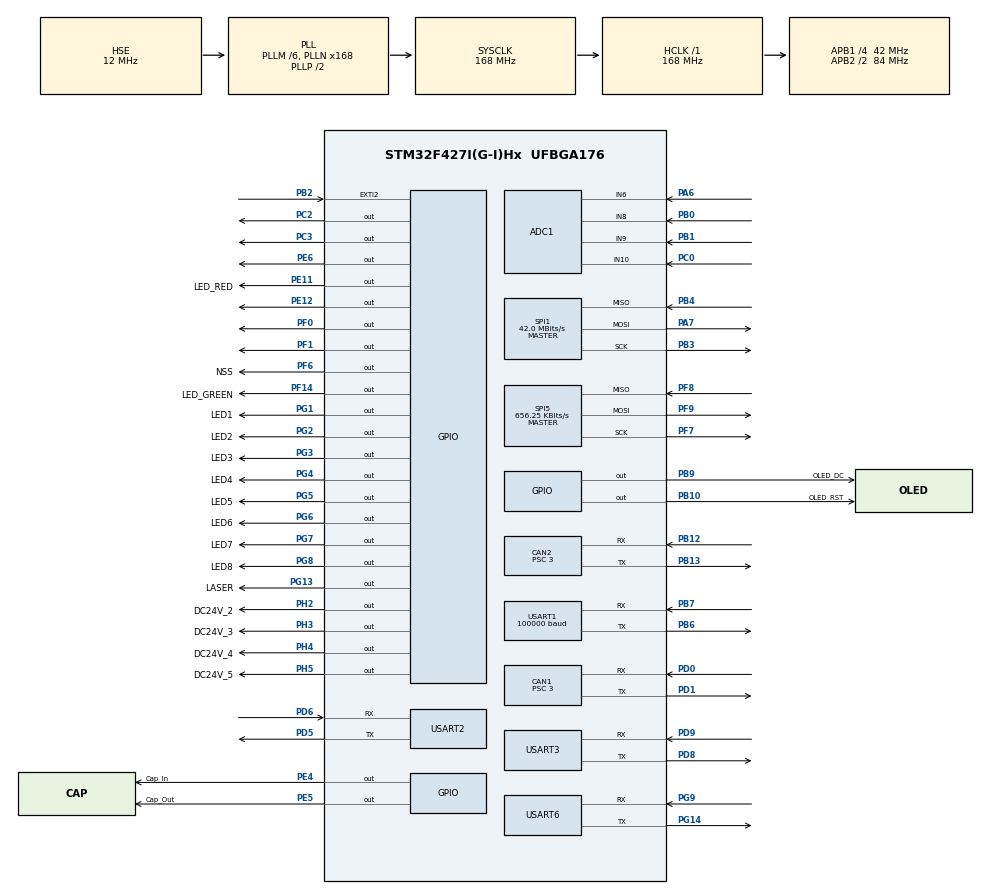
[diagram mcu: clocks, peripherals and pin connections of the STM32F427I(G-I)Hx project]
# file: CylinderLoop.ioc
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ADC1.Channel-0\#ChannelRegularConversion=ADC_CHANNEL_6
ADC1.NbrOfConversionFlag=1
ADC1.Rank-0\#ChannelRegularConversion=1
ADC1.SamplingTime-0\#ChannelRegularConversion=ADC_SAMPLETIME_3CYCLES
ADC1.master=1
CAN1.BS1=CAN_BS1_9TQ
CAN1.BS2=CAN_BS2_4TQ
CAN1.CalculateTimeBit=1000
CAN1.CalculateTimeQuantum=71.42857142857143
CAN1.Prescaler=3
CAN2.BS1=CAN_BS1_9TQ
CAN2.BS2=CAN_BS2_4TQ
CAN2.CalculateTimeBit=1000
CAN2.CalculateTimeQuantum=71.42857142857143
CAN2.Prescaler=3
Dma.Request0=USART3_RX
Dma.Request1=USART6_RX
Dma.Request2=USART6_TX
Dma.Request3=USART1_RX
Dma.Request4=USART3_TX
Dma.Request5=SPI1_TX
Dma.Request6=SPI1_RX
Dma.SPI1_RX.6.Direction=DMA_PERIPH_TO_MEMORY
Dma.SPI1_RX.6.FIFOMode=DMA_FIFOMODE_DISABLE
Dma.SPI1_RX.6.Instance=DMA2_Stream0
Dma.SPI1_RX.6.MemDataAlignment=DMA_MDATAALIGN_BYTE
Dma.SPI1_RX.6.MemInc=DMA_MINC_ENABLE
Dma.SPI1_RX.6.Mode=DMA_NORMAL
Dma.SPI1_RX.6.PeriphDataAlignment=DMA_PDATAALIGN_BYTE
Dma.SPI1_RX.6.PeriphInc=DMA_PINC_DISABLE
Dma.SPI1_RX.6.Priority=DMA_PRIORITY_LOW
Dma.SPI1_TX.5.Direction=DMA_MEMORY_TO_PERIPH
Dma.SPI1_TX.5.FIFOMode=DMA_FIFOMODE_DISABLE
Dma.SPI1_TX.5.Instance=DMA2_Stream5
Dma.SPI1_TX.5.MemDataAlignment=DMA_MDATAALIGN_BYTE
Dma.SPI1_TX.5.MemInc=DMA_MINC_ENABLE
Dma.SPI1_TX.5.Mode=DMA_NORMAL
Dma.SPI1_TX.5.PeriphDataAlignment=DMA_PDATAALIGN_BYTE
Dma.SPI1_TX.5.PeriphInc=DMA_PINC_DISABLE
Dma.SPI1_TX.5.Priority=DMA_PRIORITY_LOW
Dma.USART1_RX.3.Direction=DMA_PERIPH_TO_MEMORY
Dma.USART1_RX.3.FIFOMode=DMA_FIFOMODE_DISABLE
Dma.USART1_RX.3.Instance=DMA2_Stream2
Dma.USART1_RX.3.MemDataAlignment=DMA_MDATAALIGN_BYTE
Dma.USART1_RX.3.MemInc=DMA_MINC_ENABLE
Dma.USART1_RX.3.Mode=DMA_NORMAL
Dma.USART1_RX.3.PeriphDataAlignment=DMA_PDATAALIGN_BYTE
Dma.USART1_RX.3.PeriphInc=DMA_PINC_DISABLE
Dma.USART1_RX.3.Priority=DMA_PRIORITY_LOW
Dma.USART3_RX.0.Direction=DMA_PERIPH_TO_MEMORY
Dma.USART3_RX.0.FIFOMode=DMA_FIFOMODE_DISABLE
Dma.USART3_RX.0.Instance=DMA1_Stream1
Dma.USART3_RX.0.MemDataAlignment=DMA_MDATAALIGN_BYTE
Dma.USART3_RX.0.MemInc=DMA_MINC_ENABLE
Dma.USART3_RX.0.Mode=DMA_NORMAL
Dma.USART3_RX.0.PeriphDataAlignment=DMA_PDATAALIGN_BYTE
Dma.USART3_RX.0.PeriphInc=DMA_PINC_DISABLE
Dma.USART3_RX.0.Priority=DMA_PRIORITY_LOW
Dma.USART3_TX.4.Direction=DMA_MEMORY_TO_PERIPH
Dma.USART3_TX.4.FIFOMode=DMA_FIFOMODE_DISABLE
Dma.USART3_TX.4.Instance=DMA1_Stream3
Dma.USART3_TX.4.MemDataAlignment=DMA_MDATAALIGN_BYTE
Dma.USART3_TX.4.MemInc=DMA_MINC_ENABLE
Dma.USART3_TX.4.Mode=DMA_NORMAL
Dma.USART3_TX.4.PeriphDataAlignment=DMA_PDATAALIGN_BYTE
Dma.USART3_TX.4.PeriphInc=DMA_PINC_DISABLE
Dma.USART3_TX.4.Priority=DMA_PRIORITY_LOW
Dma.USART6_RX.1.Direction=DMA_PERIPH_TO_MEMORY
Dma.USART6_RX.1.FIFOMode=DMA_FIFOMODE_DISABLE
Dma.USART6_RX.1.Instance=DMA2_Stream1
Dma.USART6_RX.1.MemDataAlignment=DMA_MDATAALIGN_BYTE
Dma.USART6_RX.1.MemInc=DMA_MINC_ENABLE
Dma.USART6_RX.1.Mode=DMA_NORMAL
Dma.USART6_RX.1.PeriphDataAlignment=DMA_PDATAALIGN_BYTE
Dma.USART6_RX.1.PeriphInc=DMA_PINC_DISABLE
Dma.USART6_RX.1.Priority=DMA_PRIORITY_LOW
Dma.USART6_TX.2.Direction=DMA_MEMORY_TO_PERIPH
Dma.USART6_TX.2.FIFOMode=DMA_FIFOMODE_DISABLE
Dma.USART6_TX.2.Instance=DMA2_Stream6
Dma.USART6_TX.2.MemDataAlignment=DMA_MDATAALIGN_BYTE
Dma.USART6_TX.2.MemInc=DMA_MINC_ENABLE
Dma.USART6_TX.2.Mode=DMA_NORMAL
Dma.USART6_TX.2.PeriphDataAlignment=DMA_PDATAALIGN_BYTE
Dma.USART6_TX.2.PeriphInc=DMA_PINC_DISABLE
Dma.USART6_TX.2.Priority=DMA_PRIORITY_LOW
Mcu.Family=STM32F4
Mcu.Name=STM32F427I(G-I)Hx
Mcu.Package=UFBGA176
NVIC.CAN1_RX0_IRQn=true\:0\:0\:true\:false\:true\:true\:true
NVIC.CAN1_TX_IRQn=true\:0\:0\:true\:false\:true\:true\:true
NVIC.CAN2_RX0_IRQn=true\:1\:0\:true\:false\:true\:true\:true
NVIC.CAN2_TX_IRQn=true\:2\:0\:true\:false\:true\:true\:true
NVIC.DMA1_Stream1_IRQn=true\:0\:0\:false\:false\:true\:false\:true
NVIC.DMA1_Stream3_IRQn=true\:0\:0\:false\:false\:true\:false\:true
NVIC.DMA2_Stream0_IRQn=true\:0\:0\:false\:false\:true\:false\:true
NVIC.DMA2_Stream1_IRQn=true\:0\:0\:false\:false\:true\:false\:true
NVIC.DMA2_Stream2_IRQn=true\:0\:0\:false\:false\:true\:false\:true
NVIC.DMA2_Stream5_IRQn=true\:0\:0\:false\:false\:true\:false\:true
NVIC.DMA2_Stream6_IRQn=true\:0\:0\:false\:false\:true\:false\:true
NVIC.EXTI2_IRQn=true\:0\:0\:false\:false\:true\:true\:true
NVIC.PriorityGroup=NVIC_PRIORITYGROUP_4
NVIC.TIM6_DAC_IRQn=true\:3\:0\:true\:false\:true\:true\:true
NVIC.TIM7_IRQn=true\:0\:0\:true\:false\:true\:true\:true
NVIC.USART1_IRQn=true\:0\:0\:true\:false\:true\:true\:true
NVIC.USART2_IRQn=true\:0\:0\:false\:false\:true\:true\:true
NVIC.USART3_IRQn=true\:0\:0\:false\:false\:true\:true\:true
NVIC.USART6_IRQn=true\:1\:0\:true\:false\:true\:true\:true
PA1.Signal=ADCx_IN1
PA13.Mode=Serial_Wire
PA13.Signal=SYS_JTMS-SWDIO
PA14.Mode=Serial_Wire
PA14.Signal=SYS_JTCK-SWCLK
PA4.Signal=COMP_DAC1_group
PA5.Signal=COMP_DAC2_group
PA6.Signal=ADCx_IN6
PA7.Mode=Full_Duplex_Master
PA7.Signal=SPI1_MOSI
PB0.Signal=ADCx_IN8
PB1.Signal=ADCx_IN9
PB10.GPIO_Label=OLED_RST
PB10.Signal=GPIO_Output
PB12.Mode=Slave
PB12.Signal=CAN2_RX
PB13.Mode=Slave
PB13.Signal=CAN2_TX
PB2/BOOT1.Signal=GPXTI2
PB3.Mode=Full_Duplex_Master
PB3.Signal=SPI1_SCK
PB4.Mode=Full_Duplex_Master
PB4.Signal=SPI1_MISO
PB5.Signal=S_TIM3_CH2
PB6.Mode=Asynchronous
PB6.Signal=USART1_TX
PB7.Mode=Asynchronous
PB7.Signal=USART1_RX
PB9.GPIO_Label=OLED_DC
PB9.Signal=GPIO_Output
PC0.Signal=ADCx_IN10
PC14/OSC32_IN.Mode=LSE-External-Oscillator
PC14/OSC32_IN.Signal=RCC_OSC32_IN
PC15/OSC32_OUT.Mode=LSE-External-Oscillator
PC15/OSC32_OUT.Signal=RCC_OSC32_OUT
PC2.Signal=GPIO_Output
PC3.Signal=GPIO_Output
PD0.Mode=Master
PD0.Signal=CAN1_RX
PD1.Mode=Master
PD1.Signal=CAN1_TX
PD5.Mode=Asynchronous
PD5.Signal=USART2_TX
PD6.Mode=Asynchronous
PD6.Signal=USART2_RX
PD8.Mode=Asynchronous
PD8.Signal=USART3_TX
PD9.Mode=Asynchronous
PD9.Signal=USART3_RX
PE11.GPIO_Label=LED_RED
PE11.Signal=GPIO_Output
PE12.Signal=GPIO_Output
PE4.GPIO_Label=Cap_In
PE4.GPIO_PuPd=GPIO_PULLDOWN
PE4.GPIO_Speed=GPIO_SPEED_FREQ_HIGH
PE4.PinState=GPIO_PIN_RESET
PE4.Signal=GPIO_Output
PE5.GPIO_Label=Cap_Out
PE5.Signal=GPIO_Output
PE6.Signal=GPIO_Output
PF0.Signal=GPIO_Output
PF1.GPIO_PuPd=GPIO_NOPULL
PF1.PinState=GPIO_PIN_SET
PF1.Signal=GPIO_Output
PF14.GPIO_Label=LED_GREEN
PF14.Signal=GPIO_Output
PF6.GPIO_Label=NSS
PF6.Signal=GPIO_Output
PF7.Mode=Full_Duplex_Master
PF7.Signal=SPI5_SCK
PF8.Mode=Full_Duplex_Master
PF8.Signal=SPI5_MISO
PF9.Mode=Full_Duplex_Master
PF9.Signal=SPI5_MOSI
PG1.GPIO_Label=LED1
PG1.Signal=GPIO_Output
PG13.GPIO_Label=LASER
PG13.Signal=GPIO_Output
PG14.Mode=Asynchronous
PG14.Signal=USART6_TX
PG2.GPIO_Label=LED2
PG2.Signal=GPIO_Output
PG3.GPIO_Label=LED3
PG3.Signal=GPIO_Output
PG4.GPIO_Label=LED4
PG4.Signal=GPIO_Output
PG5.GPIO_Label=LED5
PG5.Signal=GPIO_Output
PG6.GPIO_Label=LED6
PG6.Signal=GPIO_Output
PG7.GPIO_Label=LED7
PG7.Signal=GPIO_Output
PG8.GPIO_Label=LED8
PG8.Signal=GPIO_Output
PG9.Mode=Asynchronous
PG9.Signal=USART6_RX
PH0/OSC_IN.Mode=HSE-External-Oscillator
PH0/OSC_IN.Signal=RCC_OSC_IN
PH1/OSC_OUT.Mode=HSE-External-Oscillator
PH1/OSC_OUT.Signal=RCC_OSC_OUT
PH2.GPIO_Label=DC24V_2
PH2.Signal=GPIO_Output
PH3.GPIO_Label=DC24V_3
PH3.Signal=GPIO_Output
PH4.GPIO_Label=DC24V_4
PH4.Signal=GPIO_Output
PH5.GPIO_Label=DC24V_5
PH5.Signal=GPIO_Output
PH6.Signal=S_TIM12_CH1
PI0.Signal=S_TIM5_CH4
PI6.Signal=S_TIM8_CH2
PI7.Signal=S_TIM8_CH3
ProjectManager.HeapSize=0x200
ProjectManager.StackSize=0x400
ProjectManager.TargetToolchain=STM32CubeIDE
RCC.48MHZClocksFreq_Value=84000000
RCC.AHBFreq_Value=168000000
RCC.APB1CLKDivider=RCC_HCLK_DIV4
RCC.APB1Freq_Value=42000000
RCC.APB1TimFreq_Value=84000000
RCC.APB2CLKDivider=RCC_HCLK_DIV2
RCC.APB2Freq_Value=84000000
RCC.APB2TimFreq_Value=168000000
RCC.CortexFreq_Value=168000000
RCC.HCLKFreq_Value=168000000
RCC.HSE_VALUE=12000000
RCC.HSI_VALUE=16000000
RCC.PLLM=6
RCC.PLLN=168
RCC.PLLSourceVirtual=RCC_PLLSOURCE_HSE
RCC.SYSCLKFreq_VALUE=168000000
RCC.SYSCLKSource=RCC_SYSCLKSOURCE_PLLCLK
RCC.VCOOutputFreq_Value=336000000
RealThread.RT-Thread.3.1.3.RTAaThreadCcRTOSJjkernel=true
RealThread.RT-Thread.3.1.3.RTOSJjRTAaThread.cmp_version0=3.1.3
RealThread.RT-Thread.3.1.3.RTOSJjRTAaThread.component0=RTOS
RealThread.RT-Thread.3.1.3.RTOSJjRTAaThread.description0=rt-thread,rt-thread kernel files
RealThread.RT-Thread.3.1.3.RTOSJjRTAaThread.diagnostic0=This component should operate correctly.
RealThread.RT-Thread.3.1.3.RTOSJjRTAaThread.group0=kernel
RealThread.RT-Thread.3.1.3.RTOSJjRTAaThread.paramName0=RTAaThreadCcRTOSJjkernel
RealThread.RT-Thread.3.1.3.RTOSJjRTAaThread.sevirity0=none
RealThread.RT-Thread.3.1.3.RTOSJjRTAaThread_bundle=RT-Thread
RealThread.RT-Thread.3.1.3.RTOSJjRTAaThread_class=RTOS
RealThread.RT-Thread.3.1.3.RTOSJjRTAaThread_name=RT-Thread
RealThread.RT-Thread.3.1.3.RTOSJjRTAaThread_size=1
RealThread.RT-Thread.3.1.3.RTOSJjRTAaThread_vendor=RealThread
RealThread.RT-Thread.3.1.3.RTOSJjRTAaThread_version=3.1.3
RealThread.RT-Thread.3.1.3.RT_USING_HEAP=1
RealThread.RT-Thread.3.1.3_CubeMXJjrtAathread_RteComponentsize=0
RealThread.RT-Thread.3.1.3_MwName0=RT-Thread
RealThread.RT-Thread.3.1.3_NumberOfMw=1
RealThread.RT-Thread.3.1.3_RTOSJjRTAaThread_RteComponentsize=0
RealThread.RT-Thread.3.1.3_description=RT-Thread Software Components
RealThread.RT-Thread.3.1.3_license=License.txt
SH.ADCx_IN1.0=ADC2_IN1
SH.ADCx_IN10.0=ADC1_IN10,IN10
SH.ADCx_IN6.0=ADC1_IN6,IN6
SH.ADCx_IN8.0=ADC1_IN8,IN8
SH.ADCx_IN9.0=ADC1_IN9,IN9
SH.COMP_DAC1_group.0=DAC_OUT1
SH.COMP_DAC2_group.0=DAC_OUT2
SH.S_TIM12_CH1.0=TIM12_CH1
SH.S_TIM3_CH2.0=TIM3_CH2
SH.S_TIM5_CH4.0=TIM5_CH4
SH.S_TIM8_CH2.0=TIM8_CH2
SH.S_TIM8_CH3.0=TIM8_CH3
SPI1.BaudRatePrescaler=SPI_BAUDRATEPRESCALER_2
SPI1.CalculateBaudRate=42.0 MBits/s
SPI1.Direction=SPI_DIRECTION_2LINES
SPI1.Mode=SPI_MODE_MASTER
SPI1.VirtualType=VM_MASTER
SPI5.BaudRatePrescaler=SPI_BAUDRATEPRESCALER_128
SPI5.CalculateBaudRate=656.25 KBits/s
SPI5.Direction=SPI_DIRECTION_2LINES
SPI5.Mode=SPI_MODE_MASTER
SPI5.VirtualType=VM_MASTER
TIM6.Period=1000
TIM6.Prescaler=84-1
TIM7.Period=1000
TIM7.Prescaler=84-1
USART1.BaudRate=100000
USART1.Mode=MODE_RX
USART1.Parity=PARITY_EVEN
USART1.VirtualMode=VM_ASYNC
USART1.WordLength=WORDLENGTH_9B
USART2.VirtualMode=VM_ASYNC
USART3.VirtualMode=VM_ASYNC
USART6.VirtualMode=VM_ASYNC
VP_ADC1_Vref_Input.Mode=IN-Vrefint
VP_FATFS_VS_Generic.Mode=User_defined
VP_RealThread.RT-Thread_VS_RTOSJjRTAaThread_3.1.3.Mode=RTOSJjRTAaThread
VP_TIM6_VS_ClockSourceINT.Mode=Enable_Timer
VP_TIM7_VS_ClockSourceINT.Mode=Enable_Timer
board=RM_frame

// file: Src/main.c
/* USER CODE BEGIN Header */
/**
  ******************************************************************************
  * @file           : main.c
  * @brief          : Main program body
  ******************************************************************************
  * @attention
  *
  * <h2><center>&copy; Copyright (c) 2021 STMicroelectronics.
  * All rights reserved.</center></h2>
  *
  * This software component is licensed by ST under BSD 3-Clause license,
  * the "License"; You may not use this file except in compliance with the
  * License. You may obtain a copy of the License at:
  *                        opensource.org/licenses/BSD-3-Clause
  *
  ******************************************************************************
  */
/* USER CODE END Header */

#include "main.h"
#include "adc.h"
#include "can.h"
#include "dma.h"
#include "fatfs.h"
#include "spi.h"
#include "tim.h"
#include "usart.h"
#include "gpio.h"
#include "app_rtthread.h"

/* USER CODE BEGIN Includes */
#include "RobotTask.h"
/* USER CODE END Includes */

void SystemClock_Config(void);

/* USER CODE BEGIN 0 */
void HAL_TIM_PeriodElapsedCallback(TIM_HandleTypeDef *htim) {
    if (htim->Instance == htim6.Instance) {
        //HAL_NVIC_DisableIRQ(TIM6_DAC_IRQn);
        MainControlLoop();
        //oled_menu->Update();
        //HAL_NVIC_EnableIRQ(TIM6_DAC_IRQn);
    }
    if(htim->Instance == htim7.Instance) {
        //RemoteKeyMouseControlLoop();
    }
}

void HAL_SPI_TxCpltCallback(SPI_HandleTypeDef *hspi){

}

void HAL_Delay(uint32_t Delay){
    rt_thread_delay(Delay);
}
/* USER CODE END 0 */

int main(void)
{

  /* MCU Configuration--------------------------------------------------------*/

  /* Reset of all peripherals, Initializes the Flash interface and the Systick. */
  HAL_Init();

  /* Configure the system clock */
  SystemClock_Config();

  /* Initialize all configured peripherals */
  MX_GPIO_Init();
  MX_DMA_Init();
  MX_CAN1_Init();
  MX_CAN2_Init();
  MX_SPI5_Init();
  MX_USART1_UART_Init();
  MX_TIM6_Init();
  MX_USART6_UART_Init();
  MX_TIM7_Init();
  MX_USART3_UART_Init();
  MX_USART2_UART_Init();
  MX_SPI1_Init();
  MX_ADC1_Init();
  MX_FATFS_Init();
  MX_RT_Thread_Init();
  /* USER CODE BEGIN 2 */
    MainInit();
    HAL_TIM_Base_Start_IT(&htim6);
  /* USER CODE END 2 */

  /* Infinite loop */
  while (1)
  {

  MX_RT_Thread_Process();
  }
}

void SystemClock_Config(void)
{
  RCC_OscInitTypeDef RCC_OscInitStruct = {0};
  RCC_ClkInitTypeDef RCC_ClkInitStruct = {0};

  /** Configure the main internal regulator output voltage
  */
  __HAL_RCC_PWR_CLK_ENABLE();
  __HAL_PWR_VOLTAGESCALING_CONFIG(PWR_REGULATOR_VOLTAGE_SCALE1);
  /** Initializes the CPU, AHB and APB busses clocks
  */
  RCC_OscInitStruct.OscillatorType = RCC_OSCILLATORTYPE_HSE;
  RCC_OscInitStruct.HSEState = RCC_HSE_ON;
  RCC_OscInitStruct.PLL.PLLState = RCC_PLL_ON;
  RCC_OscInitStruct.PLL.PLLSource = RCC_PLLSOURCE_HSE;
  RCC_OscInitStruct.PLL.PLLM = 6;
  RCC_OscInitStruct.PLL.PLLN = 168;
  RCC_OscInitStruct.PLL.PLLP = RCC_PLLP_DIV2;
  RCC_OscInitStruct.PLL.PLLQ = 4;
  if (HAL_RCC_OscConfig(&RCC_OscInitStruct) != HAL_OK)
  {
    Error_Handler();
  }
  /** Initializes the CPU, AHB and APB busses clocks
  */
  RCC_ClkInitStruct.ClockType = RCC_CLOCKTYPE_HCLK|RCC_CLOCKTYPE_SYSCLK
                              |RCC_CLOCKTYPE_PCLK1|RCC_CLOCKTYPE_PCLK2;
  RCC_ClkInitStruct.SYSCLKSource = RCC_SYSCLKSOURCE_PLLCLK;
  RCC_ClkInitStruct.AHBCLKDivider = RCC_SYSCLK_DIV1;
  RCC_ClkInitStruct.APB1CLKDivider = RCC_HCLK_DIV4;
  RCC_ClkInitStruct.APB2CLKDivider = RCC_HCLK_DIV2;

  if (HAL_RCC_ClockConfig(&RCC_ClkInitStruct, FLASH_LATENCY_5) != HAL_OK)
  {
    Error_Handler();
  }
}

void Error_Handler(void)
{
}

/************************ (C) COPYRIGHT STMicroelectronics *****END OF FILE****/
